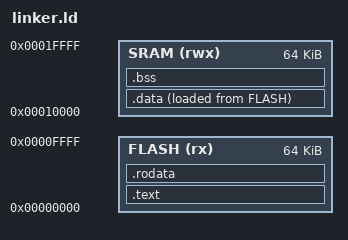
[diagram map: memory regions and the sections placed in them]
/* linker.ld - memory map of the target SoC
 *   FLASH 0x00000000, 64 KB: code, constants, initial values of .data
 *   SRAM  0x00010000, 64 KB: variables (.data, .bss) and the stack
 */
OUTPUT_ARCH(riscv)
ENTRY(_start)

MEMORY
{
    FLASH (rx)  : ORIGIN = 0x00000000, LENGTH = 64K
    SRAM  (rwx) : ORIGIN = 0x00010000, LENGTH = 64K
}

SECTIONS
{
    .text : {
        *(.text.init)
        *(.text .text.*)
    } > FLASH

    .rodata : {
        *(.rodata .rodata.* .srodata .srodata.*)
        . = ALIGN(4);
    } > FLASH

    .data : {
        _data_start = .;
        *(.data .data.* .sdata .sdata.*)
        . = ALIGN(4);
        _data_end = .;
    } > SRAM AT > FLASH
    _data_load = LOADADDR(.data);

    .bss : {
        _bss_start = .;
        *(.bss .bss.* .sbss .sbss.* COMMON)
        . = ALIGN(4);
        _bss_end = .;
    } > SRAM

    _stack_top = ORIGIN(SRAM) + LENGTH(SRAM);
}
